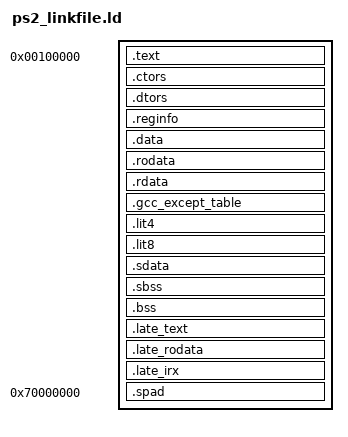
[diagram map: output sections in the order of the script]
/* GENERATED by ps2/tools/gen_arena_glue.py - do not edit.
 *
 * EE link script for the SSB64 port: the ps2sdk default linkfile
 * (Copyright 2001-2004 ps2dev, Academic Free License 2.0) plus one
 * .data and one .bss range per N64 code overlay. On the N64 every
 * syDmaLoadOverlay() re-DMAs an overlay, which resets its initialized data
 * and clears its bss; ps2/src/memory/overlay_state.c reproduces that with
 * these ranges (__ps2_<ovl>_data_start/end, __ps2_<ovl>_bss_start/end).
 */

ENTRY(__start);

PHDRS {
  text PT_LOAD;
}

SECTIONS {
	.text 0x00100000: {
		_ftext = . ;
		*(.text)
		*(.text.*)
		*(.gnu.linkonce.t*)
		KEEP(*(.init))
		KEEP(*(.fini))
		QUAD(0)
	} :text

	PROVIDE(_etext = .);
	PROVIDE(etext = .);

	.ctors ALIGN(16): {
		PROVIDE(__CTOR_LIST__ = .);
		KEEP(*crtbegin*.o(.ctors))
		KEEP(*(EXCLUDE_FILE(*crtend*.o) .ctors))
		KEEP(*(SORT(.ctors.*)))
		KEEP(*(.ctors))
		PROVIDE(__CTOR_END__ = .);
	}
	.dtors ALIGN(16): {
		PROVIDE(__DTOR_LIST__ = .);
		KEEP(*crtbegin*.o(.dtors))
		KEEP(*(EXCLUDE_FILE(*crtend*.o) .dtors))
		KEEP(*(SORT(.dtors.*)))
		KEEP(*(.dtors))
		PROVIDE(__DTOR_END__ = .);
	}

	.reginfo : { *(.reginfo) }

	.data ALIGN(128): {
		_fdata = . ;
		__ps2_ovl_data_start = .;
		. = ALIGN(16); __ps2_ovl0_data_start = .;
		*libssb_game.a:lbcommon.o(.data .data.*)
		*libssb_game.a:lbreloc.o(.data .data.*)
		*libssb_game.a:lbparticle.o(.data .data.*)
		*libssb_game.a:lbfade.o(.data .data.*)
		*libssb_game.a:lbtransition.o(.data .data.*)
		*libssb_game.a:lbbackup.o(.data .data.*)
		__ps2_ovl0_data_end = .;
		. = ALIGN(16); __ps2_ovl1_data_start = .;
		*libssb_game.a:scsubsysunused.o(.data .data.*)
		*libssb_game.a:scsubsysfighter.o(.data .data.*)
		*libssb_game.a:scsubsyscontroller.o(.data .data.*)
		*libssb_game.a:scsubsysdata.o(.data .data.*)
		*libssb_game.a:scsubsysdatamario.o(.data .data.*)
		*libssb_game.a:scsubsysdatammario.o(.data .data.*)
		*libssb_game.a:scsubsysdatanmario.o(.data .data.*)
		*libssb_game.a:scsubsysdatafox.o(.data .data.*)
		*libssb_game.a:scsubsysdatanfox.o(.data .data.*)
		*libssb_game.a:scsubsysdatadonkey.o(.data .data.*)
		*libssb_game.a:scsubsysdatandonkey.o(.data .data.*)
		*libssb_game.a:scsubsysdatagdonkey.o(.data .data.*)
		*libssb_game.a:scsubsysdatasamus.o(.data .data.*)
		*libssb_game.a:scsubsysdatansamus.o(.data .data.*)
		*libssb_game.a:scsubsysdataluigi.o(.data .data.*)
		*libssb_game.a:scsubsysdatanluigi.o(.data .data.*)
		*libssb_game.a:scsubsysdatalink.o(.data .data.*)
		*libssb_game.a:scsubsysdatanlink.o(.data .data.*)
		*libssb_game.a:scsubsysdatayoshi.o(.data .data.*)
		*libssb_game.a:scsubsysdatanyoshi.o(.data .data.*)
		*libssb_game.a:scsubsysdatacaptain.o(.data .data.*)
		*libssb_game.a:scsubsysdatancaptain.o(.data .data.*)
		*libssb_game.a:scsubsysdatakirby.o(.data .data.*)
		*libssb_game.a:scsubsysdatankirby.o(.data .data.*)
		*libssb_game.a:scsubsysdatapikachu.o(.data .data.*)
		*libssb_game.a:scsubsysdatanpikachu.o(.data .data.*)
		*libssb_game.a:scsubsysdatapurin.o(.data .data.*)
		*libssb_game.a:scsubsysdatanpurin.o(.data .data.*)
		*libssb_game.a:scsubsysdataness.o(.data .data.*)
		*libssb_game.a:scsubsysdatanness.o(.data .data.*)
		*libssb_game.a:scsubsysdataboss.o(.data .data.*)
		__ps2_ovl1_data_end = .;
		. = ALIGN(16); __ps2_ovl2_data_start = .;
		*libssb_game.a:sc1pmanager.o(.data .data.*)
		*libssb_game.a:ftmanager.o(.data .data.*)
		*libssb_game.a:ftphysics.o(.data .data.*)
		*libssb_game.a:ftanimend.o(.data .data.*)
		*libssb_game.a:mpprocess.o(.data .data.*)
		*libssb_game.a:mpcommon.o(.data .data.*)
		*libssb_game.a:ftmain.o(.data .data.*)
		*libssb_game.a:ftparam.o(.data .data.*)
		*libssb_game.a:ftanim.o(.data .data.*)
		*libssb_game.a:gmcollision.o(.data .data.*)
		*libssb_game.a:ftdisplaymain.o(.data .data.*)
		*libssb_game.a:fthammer.o(.data .data.*)
		*libssb_game.a:mpcollision.o(.data .data.*)
		*libssb_game.a:ftdisplaylights.o(.data .data.*)
		*libssb_game.a:efdisplay.o(.data .data.*)
		*libssb_game.a:efmanager.o(.data .data.*)
		*libssb_game.a:grwallpaper.o(.data .data.*)
		*libssb_game.a:grdisplay.o(.data .data.*)
		*libssb_game.a:grcommonsetup.o(.data .data.*)
		*libssb_game.a:grmainsetup.o(.data .data.*)
		*libssb_game.a:grmodelsetup.o(.data .data.*)
		*libssb_game.a:grpupupu.o(.data .data.*)
		*libssb_game.a:grsector.o(.data .data.*)
		*libssb_game.a:grzebes.o(.data .data.*)
		*libssb_game.a:gryoster.o(.data .data.*)
		*libssb_game.a:grinishie.o(.data .data.*)
		*libssb_game.a:grjungle.o(.data .data.*)
		*libssb_game.a:grhyrule.o(.data .data.*)
		*libssb_game.a:gryamabuki.o(.data .data.*)
		*libssb_game.a:grcastle.o(.data .data.*)
		*libssb_game.a:grbonus3.o(.data .data.*)
		*libssb_game.a:gmcamera.o(.data .data.*)
		*libssb_game.a:ifcommon.o(.data .data.*)
		*libssb_game.a:gmrumble.o(.data .data.*)
		*libssb_game.a:efparticle.o(.data .data.*)
		*libssb_game.a:ftkey.o(.data .data.*)
		*libssb_game.a:ifscreenflash.o(.data .data.*)
		*libssb_game.a:efground.o(.data .data.*)
		*libssb_game.a:gmcommon.o(.data .data.*)
		*libssb_game.a:ftdata.o(.data .data.*)
		*libssb_game.a:ftcommondata.o(.data .data.*)
		*libssb_game.a:gmcolscripts.o(.data .data.*)
		*libssb_game.a:ftmario.o(.data .data.*)
		*libssb_game.a:ftmmario.o(.data .data.*)
		*libssb_game.a:ftnmario.o(.data .data.*)
		*libssb_game.a:ftfox.o(.data .data.*)
		*libssb_game.a:ftnfox.o(.data .data.*)
		*libssb_game.a:ftdonkey.o(.data .data.*)
		*libssb_game.a:ftndonkey.o(.data .data.*)
		*libssb_game.a:ftgdonkey.o(.data .data.*)
		*libssb_game.a:ftsamus.o(.data .data.*)
		*libssb_game.a:ftnsamus.o(.data .data.*)
		*libssb_game.a:ftluigi.o(.data .data.*)
		*libssb_game.a:ftnluigi.o(.data .data.*)
		*libssb_game.a:ftlink.o(.data .data.*)
		*libssb_game.a:ftnlink.o(.data .data.*)
		*libssb_game.a:ftyoshi.o(.data .data.*)
		*libssb_game.a:ftnyoshi.o(.data .data.*)
		*libssb_game.a:ftcaptain.o(.data .data.*)
		*libssb_game.a:ftncaptain.o(.data .data.*)
		*libssb_game.a:ftkirby.o(.data .data.*)
		*libssb_game.a:ftnkirby.o(.data .data.*)
		*libssb_game.a:ftpikachu.o(.data .data.*)
		*libssb_game.a:ftnpikachu.o(.data .data.*)
		*libssb_game.a:ftpurin.o(.data .data.*)
		*libssb_game.a:ftnpurin.o(.data .data.*)
		*libssb_game.a:ftness.o(.data .data.*)
		*libssb_game.a:ftnness.o(.data .data.*)
		*libssb_game.a:ftboss.o(.data .data.*)
		__ps2_ovl2_data_end = .;
		. = ALIGN(16); __ps2_ovl3_data_start = .;
		*libssb_game.a:ftcomputer.o(.data .data.*)
		*libssb_game.a:ftshadow.o(.data .data.*)
		*libssb_game.a:ftcommondead.o(.data .data.*)
		*libssb_game.a:ftcommonrebirth.o(.data .data.*)
		*libssb_game.a:ftcommonsleep.o(.data .data.*)
		*libssb_game.a:ftcommonentry.o(.data .data.*)
		*libssb_game.a:ftcommonwait.o(.data .data.*)
		*libssb_game.a:ftcommonwalk.o(.data .data.*)
		*libssb_game.a:ftcommonturn.o(.data .data.*)
		*libssb_game.a:ftcommondash.o(.data .data.*)
		*libssb_game.a:ftcommonrun.o(.data .data.*)
		*libssb_game.a:ftcommonrunbrake.o(.data .data.*)
		*libssb_game.a:ftcommonturnrun.o(.data .data.*)
		*libssb_game.a:ftcommonkneebend.o(.data .data.*)
		*libssb_game.a:ftcommonjump.o(.data .data.*)
		*libssb_game.a:ftcommonfall.o(.data .data.*)
		*libssb_game.a:ftcommonjumpaerial.o(.data .data.*)
		*libssb_game.a:ftcommondamage.o(.data .data.*)
		*libssb_game.a:ftcommonwalldamage.o(.data .data.*)
		*libssb_game.a:ftcommonpass.o(.data .data.*)
		*libssb_game.a:ftcommondokan.o(.data .data.*)
		*libssb_game.a:ftcommonottotto.o(.data .data.*)
		*libssb_game.a:ftcommonlanding.o(.data .data.*)
		*libssb_game.a:ftcommonsquat.o(.data .data.*)
		*libssb_game.a:ftcommondamagefall.o(.data .data.*)
		*libssb_game.a:ftcommonfallspecial.o(.data .data.*)
		*libssb_game.a:ftcommontwister.o(.data .data.*)
		*libssb_game.a:ftcommontarucann.o(.data .data.*)
		*libssb_game.a:ftcommonstopceil.o(.data .data.*)
		*libssb_game.a:ftcommondownwaitbounce.o(.data .data.*)
		*libssb_game.a:ftcommondownstand.o(.data .data.*)
		*libssb_game.a:ftcommonpassive.o(.data .data.*)
		*libssb_game.a:ftcommonpassivestand.o(.data .data.*)
		*libssb_game.a:ftcommondownforwardback.o(.data .data.*)
		*libssb_game.a:ftcommondownattack.o(.data .data.*)
		*libssb_game.a:ftcommonrebound.o(.data .data.*)
		*libssb_game.a:ftcommoncliffcatchwait.o(.data .data.*)
		*libssb_game.a:ftcommoncliffclimb.o(.data .data.*)
		*libssb_game.a:ftcommoncliffattack.o(.data .data.*)
		*libssb_game.a:ftcommoncliffescape.o(.data .data.*)
		*libssb_game.a:ftcommonget.o(.data .data.*)
		*libssb_game.a:ftcommonitemthrow.o(.data .data.*)
		*libssb_game.a:ftcommonitemswing.o(.data .data.*)
		*libssb_game.a:ftcommonitemshoot.o(.data .data.*)
		*libssb_game.a:ftcommonhammerwalk.o(.data .data.*)
		*libssb_game.a:ftcommonhammerturn.o(.data .data.*)
		*libssb_game.a:ftcommonhammerfall.o(.data .data.*)
		*libssb_game.a:ftcommonhammerkneebend.o(.data .data.*)
		*libssb_game.a:ftcommonhammerlanding.o(.data .data.*)
		*libssb_game.a:ftcommonguard1.o(.data .data.*)
		*libssb_game.a:ftcommonguard2.o(.data .data.*)
		*libssb_game.a:ftcommonescape.o(.data .data.*)
		*libssb_game.a:ftcommonshieldbreakfly.o(.data .data.*)
		*libssb_game.a:ftcommonshieldbreakdown.o(.data .data.*)
		*libssb_game.a:ftcommonshieldbreakfall.o(.data .data.*)
		*libssb_game.a:ftcommonshieldbreakstand.o(.data .data.*)
		*libssb_game.a:ftcommonfurafura.o(.data .data.*)
		*libssb_game.a:ftcommonfurasleep.o(.data .data.*)
		*libssb_game.a:ftcommoncatch1.o(.data .data.*)
		*libssb_game.a:ftcommoncatch2.o(.data .data.*)
		*libssb_game.a:ftcommonthrow.o(.data .data.*)
		*libssb_game.a:ftkirbythrowf.o(.data .data.*)
		*libssb_game.a:ftcommoncapturepulled.o(.data .data.*)
		*libssb_game.a:ftcommoncapturewait.o(.data .data.*)
		*libssb_game.a:ftcommonthrown1.o(.data .data.*)
		*libssb_game.a:ftcommonthrown2.o(.data .data.*)
		*libssb_game.a:ftcommoncapturekirby.o(.data .data.*)
		*libssb_game.a:ftcommoncaptureyoshi.o(.data .data.*)
		*libssb_game.a:ftcommoncapturecaptain.o(.data .data.*)
		*libssb_game.a:ftdonkeythrowfwait.o(.data .data.*)
		*libssb_game.a:ftdonkeythrowfwalk.o(.data .data.*)
		*libssb_game.a:ftdonkeythrowfturn.o(.data .data.*)
		*libssb_game.a:ftdonkeythrowfkneebend.o(.data .data.*)
		*libssb_game.a:ftdonkeythrowffall.o(.data .data.*)
		*libssb_game.a:ftdonkeythrowflanding.o(.data .data.*)
		*libssb_game.a:ftdonkeythrowff.o(.data .data.*)
		*libssb_game.a:ftdonkeythrowfdamage.o(.data .data.*)
		*libssb_game.a:ftcommoncapture.o(.data .data.*)
		*libssb_game.a:ftcommonappeal.o(.data .data.*)
		*libssb_game.a:ftcommonattack1.o(.data .data.*)
		*libssb_game.a:ftcommonattack100.o(.data .data.*)
		*libssb_game.a:ftcommonattackdash.o(.data .data.*)
		*libssb_game.a:ftcommonattacks3.o(.data .data.*)
		*libssb_game.a:ftcommonattackhi3.o(.data .data.*)
		*libssb_game.a:ftcommonattacklw3.o(.data .data.*)
		*libssb_game.a:ftcommonattacks4.o(.data .data.*)
		*libssb_game.a:ftcommonattackhi4.o(.data .data.*)
		*libssb_game.a:ftcommonattacklw4.o(.data .data.*)
		*libssb_game.a:ftcommonattackair.o(.data .data.*)
		*libssb_game.a:ftcommonlandingair.o(.data .data.*)
		*libssb_game.a:ftcommonspecialair.o(.data .data.*)
		*libssb_game.a:ftcommonspecialn.o(.data .data.*)
		*libssb_game.a:ftcommonspecialhi.o(.data .data.*)
		*libssb_game.a:ftcommonspeciallw.o(.data .data.*)
		*libssb_game.a:ftpurinspecialn.o(.data .data.*)
		*libssb_game.a:ftpurinspecialhi.o(.data .data.*)
		*libssb_game.a:ftpurinspeciallw.o(.data .data.*)
		*libssb_game.a:ftkirbycopypurinspecialn.o(.data .data.*)
		*libssb_game.a:ftpikachuspecialn.o(.data .data.*)
		*libssb_game.a:ftpikachuspeciallw.o(.data .data.*)
		*libssb_game.a:ftpikachuspecialhi.o(.data .data.*)
		*libssb_game.a:ftkirbycopypikachuspecialn.o(.data .data.*)
		*libssb_game.a:ftnessspecialn.o(.data .data.*)
		*libssb_game.a:ftnessspecialhi.o(.data .data.*)
		*libssb_game.a:ftnessspeciallw.o(.data .data.*)
		*libssb_game.a:ftkirbycopynessspecialn.o(.data .data.*)
		*libssb_game.a:ftmariospecialn.o(.data .data.*)
		*libssb_game.a:ftmariospecialhi.o(.data .data.*)
		*libssb_game.a:ftmariospeciallw.o(.data .data.*)
		*libssb_game.a:ftkirbycopymariospecialn.o(.data .data.*)
		*libssb_game.a:ftkirbycopyfoxspecialn.o(.data .data.*)
		*libssb_game.a:ftkirbycopysamusspecialn.o(.data .data.*)
		*libssb_game.a:ftkirbycopydonkeyspecialn.o(.data .data.*)
		*libssb_game.a:ftbosscommon.o(.data .data.*)
		*libssb_game.a:ftbossdefault.o(.data .data.*)
		*libssb_game.a:ftbosswait.o(.data .data.*)
		*libssb_game.a:ftbossmove.o(.data .data.*)
		*libssb_game.a:ftbosshippataku.o(.data .data.*)
		*libssb_game.a:ftbossharau.o(.data .data.*)
		*libssb_game.a:ftbossokuhikouki1.o(.data .data.*)
		*libssb_game.a:ftbossokuhikouki2.o(.data .data.*)
		*libssb_game.a:ftbossokuhikouki3.o(.data .data.*)
		*libssb_game.a:ftbosswalk.o(.data .data.*)
		*libssb_game.a:ftbosswalkloop.o(.data .data.*)
		*libssb_game.a:ftbosswalkwait.o(.data .data.*)
		*libssb_game.a:ftbosswalkshoot.o(.data .data.*)
		*libssb_game.a:ftbossgootsubusuup.o(.data .data.*)
		*libssb_game.a:ftbossgootsubusuwait.o(.data .data.*)
		*libssb_game.a:ftbossgootsubusuend.o(.data .data.*)
		*libssb_game.a:ftbossgootsubusudown.o(.data .data.*)
		*libssb_game.a:ftbosstsutsuku1.o(.data .data.*)
		*libssb_game.a:ftbosstsutsuku3.o(.data .data.*)
		*libssb_game.a:ftbosstsutsuku2.o(.data .data.*)
		*libssb_game.a:ftbossdrill.o(.data .data.*)
		*libssb_game.a:ftbossokukouki.o(.data .data.*)
		*libssb_game.a:ftbossyubideppou1.o(.data .data.*)
		*libssb_game.a:ftbossyubideppou3.o(.data .data.*)
		*libssb_game.a:ftbossyubideppou2.o(.data .data.*)
		*libssb_game.a:ftbossokupunch1.o(.data .data.*)
		*libssb_game.a:ftbossokupunch2.o(.data .data.*)
		*libssb_game.a:ftbossokupunch3.o(.data .data.*)
		*libssb_game.a:ftbossokutsubushi.o(.data .data.*)
		*libssb_game.a:ftbossokutsubushistart.o(.data .data.*)
		*libssb_game.a:ftbossdeadleft.o(.data .data.*)
		*libssb_game.a:ftbossdeadcenter.o(.data .data.*)
		*libssb_game.a:ftbossdeadright.o(.data .data.*)
		*libssb_game.a:ftbossappear.o(.data .data.*)
		*libssb_game.a:ftdonkeyspecialn.o(.data .data.*)
		*libssb_game.a:ftdonkeyspecialhi.o(.data .data.*)
		*libssb_game.a:ftdonkeyspeciallw.o(.data .data.*)
		*libssb_game.a:ftfoxspecialn.o(.data .data.*)
		*libssb_game.a:ftfoxspecialhi.o(.data .data.*)
		*libssb_game.a:ftfoxspeciallw.o(.data .data.*)
		*libssb_game.a:ftsamusspecialn.o(.data .data.*)
		*libssb_game.a:ftsamusspecialhi.o(.data .data.*)
		*libssb_game.a:ftsamusspeciallw.o(.data .data.*)
		*libssb_game.a:ftyoshispecialn.o(.data .data.*)
		*libssb_game.a:ftyoshispecialhi.o(.data .data.*)
		*libssb_game.a:ftyoshispeciallw.o(.data .data.*)
		*libssb_game.a:ftkirbycopyyoshispecialn.o(.data .data.*)
		*libssb_game.a:ftcaptainspecialn.o(.data .data.*)
		*libssb_game.a:ftcaptainspeciallw.o(.data .data.*)
		*libssb_game.a:ftcaptainspecialhi.o(.data .data.*)
		*libssb_game.a:ftkirbycopycaptainspecialn.o(.data .data.*)
		*libssb_game.a:ftkirbyspecialhi.o(.data .data.*)
		*libssb_game.a:ftkirbyspeciallw.o(.data .data.*)
		*libssb_game.a:ftkirbyspecialn.o(.data .data.*)
		*libssb_game.a:ftlinkspecialn.o(.data .data.*)
		*libssb_game.a:ftlinkspecialhi.o(.data .data.*)
		*libssb_game.a:ftlinkspeciallw.o(.data .data.*)
		*libssb_game.a:ftkirbycopylinkspecialn.o(.data .data.*)
		*libssb_game.a:ftpublic.o(.data .data.*)
		*libssb_game.a:wpmanager.o(.data .data.*)
		*libssb_game.a:wpprocess.o(.data .data.*)
		*libssb_game.a:wpdisplay.o(.data .data.*)
		*libssb_game.a:wpmap.o(.data .data.*)
		*libssb_game.a:wpmain.o(.data .data.*)
		*libssb_game.a:wpmariofireball.o(.data .data.*)
		*libssb_game.a:wpfoxblaster.o(.data .data.*)
		*libssb_game.a:wpsamuschargeshot.o(.data .data.*)
		*libssb_game.a:wpsamusbomb.o(.data .data.*)
		*libssb_game.a:wppikachuthunderjolt.o(.data .data.*)
		*libssb_game.a:wppikachuthunder.o(.data .data.*)
		*libssb_game.a:wpnesspkfire.o(.data .data.*)
		*libssb_game.a:wpnesspkthunder.o(.data .data.*)
		*libssb_game.a:wpkirbycutter.o(.data .data.*)
		*libssb_game.a:wpyoshieggthrow.o(.data .data.*)
		*libssb_game.a:wpyoshistar.o(.data .data.*)
		*libssb_game.a:wplinkspinattack.o(.data .data.*)
		*libssb_game.a:wplinkboomerang.o(.data .data.*)
		*libssb_game.a:wpbossbullet.o(.data .data.*)
		*libssb_game.a:itmanager.o(.data .data.*)
		*libssb_game.a:itprocess.o(.data .data.*)
		*libssb_game.a:itvisuals.o(.data .data.*)
		*libssb_game.a:itdisplay.o(.data .data.*)
		*libssb_game.a:itmain.o(.data .data.*)
		*libssb_game.a:itmap.o(.data .data.*)
		*libssb_game.a:itcapsule.o(.data .data.*)
		*libssb_game.a:ittomato.o(.data .data.*)
		*libssb_game.a:itheart.o(.data .data.*)
		*libssb_game.a:itstar.o(.data .data.*)
		*libssb_game.a:itsword.o(.data .data.*)
		*libssb_game.a:itbat.o(.data .data.*)
		*libssb_game.a:itharisen.o(.data .data.*)
		*libssb_game.a:itlgun.o(.data .data.*)
		*libssb_game.a:itfflower.o(.data .data.*)
		*libssb_game.a:ithammer.o(.data .data.*)
		*libssb_game.a:itmsbomb.o(.data .data.*)
		*libssb_game.a:itbombhei.o(.data .data.*)
		*libssb_game.a:itstarrod.o(.data .data.*)
		*libssb_game.a:itgshell.o(.data .data.*)
		*libssb_game.a:itbox.o(.data .data.*)
		*libssb_game.a:ittaru.o(.data .data.*)
		*libssb_game.a:itrshell.o(.data .data.*)
		*libssb_game.a:itnbumper.o(.data .data.*)
		*libssb_game.a:itpowerblock.o(.data .data.*)
		*libssb_game.a:itglucky.o(.data .data.*)
		*libssb_game.a:itmball.o(.data .data.*)
		*libssb_game.a:itpakkun.o(.data .data.*)
		*libssb_game.a:itgbumper.o(.data .data.*)
		*libssb_game.a:itiwark.o(.data .data.*)
		*libssb_game.a:itkabigon.o(.data .data.*)
		*libssb_game.a:ittosakinto.o(.data .data.*)
		*libssb_game.a:itmew.o(.data .data.*)
		*libssb_game.a:itnyars.o(.data .data.*)
		*libssb_game.a:itlizardon.o(.data .data.*)
		*libssb_game.a:itspear.o(.data .data.*)
		*libssb_game.a:itkamex.o(.data .data.*)
		*libssb_game.a:itmlucky.o(.data .data.*)
		*libssb_game.a:itegg.o(.data .data.*)
		*libssb_game.a:itstarmie.o(.data .data.*)
		*libssb_game.a:itsawamura.o(.data .data.*)
		*libssb_game.a:itdogas.o(.data .data.*)
		*libssb_game.a:itpippi.o(.data .data.*)
		*libssb_game.a:itmarumine.o(.data .data.*)
		*libssb_game.a:itporygon.o(.data .data.*)
		*libssb_game.a:ithitokage.o(.data .data.*)
		*libssb_game.a:itfushigibana.o(.data .data.*)
		*libssb_game.a:ittarubomb.o(.data .data.*)
		*libssb_game.a:itnesspkfire.o(.data .data.*)
		*libssb_game.a:itlinkbomb.o(.data .data.*)
		__ps2_ovl3_data_end = .;
		. = ALIGN(16); __ps2_ovl4_data_start = .;
		*libssb_game.a:scvsbattle.o(.data .data.*)
		*libssb_game.a:scvsbattlefiles.o(.data .data.*)
		__ps2_ovl4_data_end = .;
		. = ALIGN(16); __ps2_ovl5_data_start = .;
		*libssb_game.a:mvunknownmario.o(.data .data.*)
		__ps2_ovl5_data_end = .;
		. = ALIGN(16); __ps2_ovl6_data_start = .;
		*libssb_game.a:sc1pbonusstage.o(.data .data.*)
		*libssb_game.a:sc1pbonusstagefiles.o(.data .data.*)
		*libssb_game.a:ittarget.o(.data .data.*)
		__ps2_ovl6_data_end = .;
		. = ALIGN(16); __ps2_ovl7_data_start = .;
		*libssb_game.a:sc1ptrainingmode.o(.data .data.*)
		__ps2_ovl7_data_end = .;
		. = ALIGN(16); __ps2_ovl8_data_start = .;
		*libssb_game.a:ovl8_0.o(.data .data.*)
		*libssb_game.a:ovl8_1.o(.data .data.*)
		*libssb_game.a:ovl8_2.o(.data .data.*)
		*libssb_game.a:ovl8_3.o(.data .data.*)
		*libssb_game.a:ovl8_4.o(.data .data.*)
		*libssb_game.a:ovl8_5.o(.data .data.*)
		*libssb_game.a:ovl8_6.o(.data .data.*)
		*libssb_game.a:ovl8_6_1.o(.data .data.*)
		*libssb_game.a:ovl8_7.o(.data .data.*)
		*libssb_game.a:ovl8_8.o(.data .data.*)
		*libssb_game.a:ovl8_8_2.o(.data .data.*)
		*libssb_game.a:ovl8_9.o(.data .data.*)
		*libssb_game.a:ovl8_10.o(.data .data.*)
		*libssb_game.a:ovl8_11.o(.data .data.*)
		*libssb_game.a:ovl8_11_1.o(.data .data.*)
		*libssb_game.a:ovl8_12.o(.data .data.*)
		*libssb_game.a:ovl8_13.o(.data .data.*)
		*libssb_game.a:ovl8_13_2.o(.data .data.*)
		*libssb_game.a:ovl8_14.o(.data .data.*)
		*libssb_game.a:ovl8_15.o(.data .data.*)
		*libssb_game.a:ovl8_16.o(.data .data.*)
		*libssb_game.a:ovl8_17.o(.data .data.*)
		*libssb_game.a:ovl8_18.o(.data .data.*)
		*libssb_game.a:ovl8_19.o(.data .data.*)
		*libssb_game.a:ovl8_20.o(.data .data.*)
		*libssb_game.a:ovl8_21.o(.data .data.*)
		*libssb_game.a:ovl8_22.o(.data .data.*)
		*libssb_game.a:ovl8_23.o(.data .data.*)
		*libssb_game.a:ovl8_24.o(.data .data.*)
		*libssb_game.a:ovl8_25.o(.data .data.*)
		*libssb_game.a:ovl8_26.o(.data .data.*)
		*libssb_game.a:ovl8_27.o(.data .data.*)
		*libssb_game.a:ovl8_28.o(.data .data.*)
		*libssb_game.a:ovl8_29.o(.data .data.*)
		*libssb_game.a:ovl8_30.o(.data .data.*)
		*libssb_game.a:ovl8_31.o(.data .data.*)
		*libssb_game.a:ovl8_32.o(.data .data.*)
		*libssb_game.a:ovl8_bss.o(.data .data.*)
		__ps2_ovl8_data_end = .;
		. = ALIGN(16); __ps2_ovl9_data_start = .;
		*libssb_game.a:dbmenu.o(.data .data.*)
		__ps2_ovl9_data_end = .;
		. = ALIGN(16); __ps2_ovl10_data_start = .;
		*libssb_game.a:mntitle.o(.data .data.*)
		*libssb_game.a:mntitlefiles.o(.data .data.*)
		__ps2_ovl10_data_end = .;
		. = ALIGN(16); __ps2_ovl11_data_start = .;
		*libssb_game.a:mnnocontroller.o(.data .data.*)
		*libssb_game.a:mnnocontrollerfiles.o(.data .data.*)
		__ps2_ovl11_data_end = .;
		. = ALIGN(16); __ps2_ovl12_data_start = .;
		*libssb_game.a:dbmaps.o(.data .data.*)
		__ps2_ovl12_data_end = .;
		. = ALIGN(16); __ps2_ovl13_data_start = .;
		*libssb_game.a:dbcube.o(.data .data.*)
		__ps2_ovl13_data_end = .;
		. = ALIGN(16); __ps2_ovl14_data_start = .;
		*libssb_game.a:dbbattle.o(.data .data.*)
		__ps2_ovl14_data_end = .;
		. = ALIGN(16); __ps2_ovl15_data_start = .;
		*libssb_game.a:dbfalls.o(.data .data.*)
		__ps2_ovl15_data_end = .;
		. = ALIGN(16); __ps2_ovl16_data_start = .;
		*libssb_game.a:mnunusedfighters.o(.data .data.*)
		__ps2_ovl16_data_end = .;
		. = ALIGN(16); __ps2_ovl17_data_start = .;
		*libssb_game.a:mnmodeselect.o(.data .data.*)
		__ps2_ovl17_data_end = .;
		. = ALIGN(16); __ps2_ovl18_data_start = .;
		*libssb_game.a:mn1pmode.o(.data .data.*)
		__ps2_ovl18_data_end = .;
		. = ALIGN(16); __ps2_ovl19_data_start = .;
		*libssb_game.a:mnvsmode.o(.data .data.*)
		__ps2_ovl19_data_end = .;
		. = ALIGN(16); __ps2_ovl20_data_start = .;
		*libssb_game.a:mnvsoptions.o(.data .data.*)
		__ps2_ovl20_data_end = .;
		. = ALIGN(16); __ps2_ovl21_data_start = .;
		*libssb_game.a:mnvsitemswitch.o(.data .data.*)
		__ps2_ovl21_data_end = .;
		. = ALIGN(16); __ps2_ovl22_data_start = .;
		*libssb_game.a:mnmessage.o(.data .data.*)
		__ps2_ovl22_data_end = .;
		. = ALIGN(16); __ps2_ovl23_data_start = .;
		*libssb_game.a:sc1pchallenger.o(.data .data.*)
		__ps2_ovl23_data_end = .;
		. = ALIGN(16); __ps2_ovl24_data_start = .;
		*libssb_game.a:sc1pintro.o(.data .data.*)
		__ps2_ovl24_data_end = .;
		. = ALIGN(16); __ps2_ovl25_data_start = .;
		*libssb_game.a:mnscreenadjust.o(.data .data.*)
		__ps2_ovl25_data_end = .;
		. = ALIGN(16); __ps2_ovl26_data_start = .;
		*libssb_game.a:mnplayersvs.o(.data .data.*)
		__ps2_ovl26_data_end = .;
		. = ALIGN(16); __ps2_ovl27_data_start = .;
		*libssb_game.a:mnplayers1pgame.o(.data .data.*)
		__ps2_ovl27_data_end = .;
		. = ALIGN(16); __ps2_ovl28_data_start = .;
		*libssb_game.a:mnplayers1ptraining.o(.data .data.*)
		__ps2_ovl28_data_end = .;
		. = ALIGN(16); __ps2_ovl29_data_start = .;
		*libssb_game.a:mnplayers1pbonus.o(.data .data.*)
		__ps2_ovl29_data_end = .;
		. = ALIGN(16); __ps2_ovl30_data_start = .;
		*libssb_game.a:mnmaps.o(.data .data.*)
		__ps2_ovl30_data_end = .;
		. = ALIGN(16); __ps2_ovl31_data_start = .;
		*libssb_game.a:mnvsresults.o(.data .data.*)
		__ps2_ovl31_data_end = .;
		. = ALIGN(16); __ps2_ovl32_data_start = .;
		*libssb_game.a:mnvsrecord.o(.data .data.*)
		__ps2_ovl32_data_end = .;
		. = ALIGN(16); __ps2_ovl33_data_start = .;
		*libssb_game.a:mncharacters.o(.data .data.*)
		__ps2_ovl33_data_end = .;
		. = ALIGN(16); __ps2_ovl34_data_start = .;
		*libssb_game.a:mvopeningroom.o(.data .data.*)
		__ps2_ovl34_data_end = .;
		. = ALIGN(16); __ps2_ovl35_data_start = .;
		*libssb_game.a:mvopeningportraits.o(.data .data.*)
		__ps2_ovl35_data_end = .;
		. = ALIGN(16); __ps2_ovl36_data_start = .;
		*libssb_game.a:mvopeningmario.o(.data .data.*)
		__ps2_ovl36_data_end = .;
		. = ALIGN(16); __ps2_ovl37_data_start = .;
		*libssb_game.a:mvopeningdonkey.o(.data .data.*)
		__ps2_ovl37_data_end = .;
		. = ALIGN(16); __ps2_ovl38_data_start = .;
		*libssb_game.a:mvopeningsamus.o(.data .data.*)
		__ps2_ovl38_data_end = .;
		. = ALIGN(16); __ps2_ovl39_data_start = .;
		*libssb_game.a:mvopeningfox.o(.data .data.*)
		__ps2_ovl39_data_end = .;
		. = ALIGN(16); __ps2_ovl40_data_start = .;
		*libssb_game.a:mvopeninglink.o(.data .data.*)
		__ps2_ovl40_data_end = .;
		. = ALIGN(16); __ps2_ovl41_data_start = .;
		*libssb_game.a:mvopeningyoshi.o(.data .data.*)
		__ps2_ovl41_data_end = .;
		. = ALIGN(16); __ps2_ovl42_data_start = .;
		*libssb_game.a:mvopeningpikachu.o(.data .data.*)
		__ps2_ovl42_data_end = .;
		. = ALIGN(16); __ps2_ovl43_data_start = .;
		*libssb_game.a:mvopeningkirby.o(.data .data.*)
		__ps2_ovl43_data_end = .;
		. = ALIGN(16); __ps2_ovl44_data_start = .;
		*libssb_game.a:mvopeningrun.o(.data .data.*)
		__ps2_ovl44_data_end = .;
		. = ALIGN(16); __ps2_ovl45_data_start = .;
		*libssb_game.a:mvopeningyoster.o(.data .data.*)
		__ps2_ovl45_data_end = .;
		. = ALIGN(16); __ps2_ovl46_data_start = .;
		*libssb_game.a:mvopeningcliff.o(.data .data.*)
		__ps2_ovl46_data_end = .;
		. = ALIGN(16); __ps2_ovl47_data_start = .;
		*libssb_game.a:mvopeningstandoff.o(.data .data.*)
		__ps2_ovl47_data_end = .;
		. = ALIGN(16); __ps2_ovl48_data_start = .;
		*libssb_game.a:mvopeningyamabuki.o(.data .data.*)
		__ps2_ovl48_data_end = .;
		. = ALIGN(16); __ps2_ovl49_data_start = .;
		*libssb_game.a:mvopeningclash.o(.data .data.*)
		__ps2_ovl49_data_end = .;
		. = ALIGN(16); __ps2_ovl50_data_start = .;
		*libssb_game.a:mvopeningsector.o(.data .data.*)
		__ps2_ovl50_data_end = .;
		. = ALIGN(16); __ps2_ovl51_data_start = .;
		*libssb_game.a:mvopeningjungle.o(.data .data.*)
		__ps2_ovl51_data_end = .;
		. = ALIGN(16); __ps2_ovl52_data_start = .;
		*libssb_game.a:mvopeningnewcomers.o(.data .data.*)
		__ps2_ovl52_data_end = .;
		. = ALIGN(16); __ps2_ovl53_data_start = .;
		*libssb_game.a:mnbackupclear.o(.data .data.*)
		__ps2_ovl53_data_end = .;
		. = ALIGN(16); __ps2_ovl54_data_start = .;
		*libssb_game.a:mvending.o(.data .data.*)
		__ps2_ovl54_data_end = .;
		. = ALIGN(16); __ps2_ovl55_data_start = .;
		*libssb_game.a:mn1pcontinue.o(.data .data.*)
		__ps2_ovl55_data_end = .;
		. = ALIGN(16); __ps2_ovl56_data_start = .;
		*libssb_game.a:sc1pstageclear.o(.data .data.*)
		__ps2_ovl56_data_end = .;
		. = ALIGN(16); __ps2_ovl57_data_start = .;
		*libssb_game.a:mncongra.o(.data .data.*)
		__ps2_ovl57_data_end = .;
		. = ALIGN(16); __ps2_ovl58_data_start = .;
		*libssb_game.a:mnstartup.o(.data .data.*)
		__ps2_ovl58_data_end = .;
		. = ALIGN(16); __ps2_ovl59_data_start = .;
		*libssb_game.a:scstaffroll.o(.data .data.*)
		__ps2_ovl59_data_end = .;
		. = ALIGN(16); __ps2_ovl60_data_start = .;
		*libssb_game.a:mnoption.o(.data .data.*)
		__ps2_ovl60_data_end = .;
		. = ALIGN(16); __ps2_ovl61_data_start = .;
		*libssb_game.a:mndata.o(.data .data.*)
		__ps2_ovl61_data_end = .;
		. = ALIGN(16); __ps2_ovl62_data_start = .;
		*libssb_game.a:mnsoundtest.o(.data .data.*)
		__ps2_ovl62_data_end = .;
		. = ALIGN(16); __ps2_ovl63_data_start = .;
		*libssb_game.a:scexplain.o(.data .data.*)
		*libssb_game.a:scexplainfiles.o(.data .data.*)
		__ps2_ovl63_data_end = .;
		. = ALIGN(16); __ps2_ovl64_data_start = .;
		*libssb_game.a:scautodemo.o(.data .data.*)
		*libssb_game.a:scautodemofiles.o(.data .data.*)
		__ps2_ovl64_data_end = .;
		. = ALIGN(16); __ps2_ovl65_data_start = .;
		*libssb_game.a:sc1pgame.o(.data .data.*)
		*libssb_game.a:sc1pgameboss.o(.data .data.*)
		__ps2_ovl65_data_end = .;
		. = ALIGN(16); __ps2_scmanager_data_start = .;
		*libssb_game.a:scmanager.o(.data .data.*)
		__ps2_scmanager_data_end = .;
		__ps2_ovl_data_end = .;
		*(EXCLUDE_FILE(*sdr_irx.o) .data)
		*(EXCLUDE_FILE(*sdr_irx.o) .data.*)
		*(.gnu.linkonce.d*)
		SORT(CONSTRUCTORS)
	}

	.rodata ALIGN(128): {
		*(.rodata)
		*(.rodata.*)
		*(.gnu.linkonce.r*)
	}

	.rdata ALIGN(128): { *(.rdata) }
	.gcc_except_table ALIGN(128): { *(.gcc_except_table) }

	_gp = ALIGN(128) + 0x7ff0;
	.lit4 ALIGN(128): { *(.lit4) }
	.lit8 ALIGN(128): { *(.lit8) }

	.sdata ALIGN(128): {
		*(.sdata)
		*(.sdata.*)
		*(.gnu.linkonce.s*)
	}

	_edata = .;
	PROVIDE(edata = .);

	.sbss ALIGN(128) : {
		_fbss = . ;
		*(.sbss)
		*(.sbss.*)
		*(.gnu.linkonce.sb*)
		*(.scommon)
	}

	.bss ALIGN(128) : {
		. = ALIGN(16); __ps2_ovl0_bss_start = .;
		*libssb_game.a:lbcommon.o(.bss .bss.* COMMON)
		*libssb_game.a:lbreloc.o(.bss .bss.* COMMON)
		*libssb_game.a:lbparticle.o(.bss .bss.* COMMON)
		*libssb_game.a:lbfade.o(.bss .bss.* COMMON)
		*libssb_game.a:lbtransition.o(.bss .bss.* COMMON)
		*libssb_game.a:lbbackup.o(.bss .bss.* COMMON)
		__ps2_ovl0_bss_end = .;
		. = ALIGN(16); __ps2_ovl1_bss_start = .;
		*libssb_game.a:scsubsysunused.o(.bss .bss.* COMMON)
		*libssb_game.a:scsubsysfighter.o(.bss .bss.* COMMON)
		*libssb_game.a:scsubsyscontroller.o(.bss .bss.* COMMON)
		*libssb_game.a:scsubsysdata.o(.bss .bss.* COMMON)
		*libssb_game.a:scsubsysdatamario.o(.bss .bss.* COMMON)
		*libssb_game.a:scsubsysdatammario.o(.bss .bss.* COMMON)
		*libssb_game.a:scsubsysdatanmario.o(.bss .bss.* COMMON)
		*libssb_game.a:scsubsysdatafox.o(.bss .bss.* COMMON)
		*libssb_game.a:scsubsysdatanfox.o(.bss .bss.* COMMON)
		*libssb_game.a:scsubsysdatadonkey.o(.bss .bss.* COMMON)
		*libssb_game.a:scsubsysdatandonkey.o(.bss .bss.* COMMON)
		*libssb_game.a:scsubsysdatagdonkey.o(.bss .bss.* COMMON)
		*libssb_game.a:scsubsysdatasamus.o(.bss .bss.* COMMON)
		*libssb_game.a:scsubsysdatansamus.o(.bss .bss.* COMMON)
		*libssb_game.a:scsubsysdataluigi.o(.bss .bss.* COMMON)
		*libssb_game.a:scsubsysdatanluigi.o(.bss .bss.* COMMON)
		*libssb_game.a:scsubsysdatalink.o(.bss .bss.* COMMON)
		*libssb_game.a:scsubsysdatanlink.o(.bss .bss.* COMMON)
		*libssb_game.a:scsubsysdatayoshi.o(.bss .bss.* COMMON)
		*libssb_game.a:scsubsysdatanyoshi.o(.bss .bss.* COMMON)
		*libssb_game.a:scsubsysdatacaptain.o(.bss .bss.* COMMON)
		*libssb_game.a:scsubsysdatancaptain.o(.bss .bss.* COMMON)
		*libssb_game.a:scsubsysdatakirby.o(.bss .bss.* COMMON)
		*libssb_game.a:scsubsysdatankirby.o(.bss .bss.* COMMON)
		*libssb_game.a:scsubsysdatapikachu.o(.bss .bss.* COMMON)
		*libssb_game.a:scsubsysdatanpikachu.o(.bss .bss.* COMMON)
		*libssb_game.a:scsubsysdatapurin.o(.bss .bss.* COMMON)
		*libssb_game.a:scsubsysdatanpurin.o(.bss .bss.* COMMON)
		*libssb_game.a:scsubsysdataness.o(.bss .bss.* COMMON)
		*libssb_game.a:scsubsysdatanness.o(.bss .bss.* COMMON)
		*libssb_game.a:scsubsysdataboss.o(.bss .bss.* COMMON)
		__ps2_ovl1_bss_end = .;
		. = ALIGN(16); __ps2_ovl2_bss_start = .;
		*libssb_game.a:sc1pmanager.o(.bss .bss.* COMMON)
		*libssb_game.a:ftmanager.o(.bss .bss.* COMMON)
		*libssb_game.a:ftphysics.o(.bss .bss.* COMMON)
		*libssb_game.a:ftanimend.o(.bss .bss.* COMMON)
		*libssb_game.a:mpprocess.o(.bss .bss.* COMMON)
		*libssb_game.a:mpcommon.o(.bss .bss.* COMMON)
		*libssb_game.a:ftmain.o(.bss .bss.* COMMON)
		*libssb_game.a:ftparam.o(.bss .bss.* COMMON)
		*libssb_game.a:ftanim.o(.bss .bss.* COMMON)
		*libssb_game.a:gmcollision.o(.bss .bss.* COMMON)
		*libssb_game.a:ftdisplaymain.o(.bss .bss.* COMMON)
		*libssb_game.a:fthammer.o(.bss .bss.* COMMON)
		*libssb_game.a:mpcollision.o(.bss .bss.* COMMON)
		*libssb_game.a:ftdisplaylights.o(.bss .bss.* COMMON)
		*libssb_game.a:efdisplay.o(.bss .bss.* COMMON)
		*libssb_game.a:efmanager.o(.bss .bss.* COMMON)
		*libssb_game.a:grwallpaper.o(.bss .bss.* COMMON)
		*libssb_game.a:grdisplay.o(.bss .bss.* COMMON)
		*libssb_game.a:grcommonsetup.o(.bss .bss.* COMMON)
		*libssb_game.a:grmainsetup.o(.bss .bss.* COMMON)
		*libssb_game.a:grmodelsetup.o(.bss .bss.* COMMON)
		*libssb_game.a:grpupupu.o(.bss .bss.* COMMON)
		*libssb_game.a:grsector.o(.bss .bss.* COMMON)
		*libssb_game.a:grzebes.o(.bss .bss.* COMMON)
		*libssb_game.a:gryoster.o(.bss .bss.* COMMON)
		*libssb_game.a:grinishie.o(.bss .bss.* COMMON)
		*libssb_game.a:grjungle.o(.bss .bss.* COMMON)
		*libssb_game.a:grhyrule.o(.bss .bss.* COMMON)
		*libssb_game.a:gryamabuki.o(.bss .bss.* COMMON)
		*libssb_game.a:grcastle.o(.bss .bss.* COMMON)
		*libssb_game.a:grbonus3.o(.bss .bss.* COMMON)
		*libssb_game.a:gmcamera.o(.bss .bss.* COMMON)
		*libssb_game.a:ifcommon.o(.bss .bss.* COMMON)
		*libssb_game.a:gmrumble.o(.bss .bss.* COMMON)
		*libssb_game.a:efparticle.o(.bss .bss.* COMMON)
		*libssb_game.a:ftkey.o(.bss .bss.* COMMON)
		*libssb_game.a:ifscreenflash.o(.bss .bss.* COMMON)
		*libssb_game.a:efground.o(.bss .bss.* COMMON)
		*libssb_game.a:gmcommon.o(.bss .bss.* COMMON)
		*libssb_game.a:ftdata.o(.bss .bss.* COMMON)
		*libssb_game.a:ftcommondata.o(.bss .bss.* COMMON)
		*libssb_game.a:gmcolscripts.o(.bss .bss.* COMMON)
		*libssb_game.a:ftmario.o(.bss .bss.* COMMON)
		*libssb_game.a:ftmmario.o(.bss .bss.* COMMON)
		*libssb_game.a:ftnmario.o(.bss .bss.* COMMON)
		*libssb_game.a:ftfox.o(.bss .bss.* COMMON)
		*libssb_game.a:ftnfox.o(.bss .bss.* COMMON)
		*libssb_game.a:ftdonkey.o(.bss .bss.* COMMON)
		*libssb_game.a:ftndonkey.o(.bss .bss.* COMMON)
		*libssb_game.a:ftgdonkey.o(.bss .bss.* COMMON)
		*libssb_game.a:ftsamus.o(.bss .bss.* COMMON)
		*libssb_game.a:ftnsamus.o(.bss .bss.* COMMON)
		*libssb_game.a:ftluigi.o(.bss .bss.* COMMON)
		*libssb_game.a:ftnluigi.o(.bss .bss.* COMMON)
		*libssb_game.a:ftlink.o(.bss .bss.* COMMON)
		*libssb_game.a:ftnlink.o(.bss .bss.* COMMON)
		*libssb_game.a:ftyoshi.o(.bss .bss.* COMMON)
		*libssb_game.a:ftnyoshi.o(.bss .bss.* COMMON)
		*libssb_game.a:ftcaptain.o(.bss .bss.* COMMON)
		*libssb_game.a:ftncaptain.o(.bss .bss.* COMMON)
		*libssb_game.a:ftkirby.o(.bss .bss.* COMMON)
		*libssb_game.a:ftnkirby.o(.bss .bss.* COMMON)
		*libssb_game.a:ftpikachu.o(.bss .bss.* COMMON)
		*libssb_game.a:ftnpikachu.o(.bss .bss.* COMMON)
		*libssb_game.a:ftpurin.o(.bss .bss.* COMMON)
		*libssb_game.a:ftnpurin.o(.bss .bss.* COMMON)
		*libssb_game.a:ftness.o(.bss .bss.* COMMON)
		*libssb_game.a:ftnness.o(.bss .bss.* COMMON)
		*libssb_game.a:ftboss.o(.bss .bss.* COMMON)
		__ps2_ovl2_bss_end = .;
		. = ALIGN(16); __ps2_ovl3_bss_start = .;
		*libssb_game.a:ftcomputer.o(.bss .bss.* COMMON)
		*libssb_game.a:ftshadow.o(.bss .bss.* COMMON)
		*libssb_game.a:ftcommondead.o(.bss .bss.* COMMON)
		*libssb_game.a:ftcommonrebirth.o(.bss .bss.* COMMON)
		*libssb_game.a:ftcommonsleep.o(.bss .bss.* COMMON)
		*libssb_game.a:ftcommonentry.o(.bss .bss.* COMMON)
		*libssb_game.a:ftcommonwait.o(.bss .bss.* COMMON)
		*libssb_game.a:ftcommonwalk.o(.bss .bss.* COMMON)
		*libssb_game.a:ftcommonturn.o(.bss .bss.* COMMON)
		*libssb_game.a:ftcommondash.o(.bss .bss.* COMMON)
		*libssb_game.a:ftcommonrun.o(.bss .bss.* COMMON)
		*libssb_game.a:ftcommonrunbrake.o(.bss .bss.* COMMON)
		*libssb_game.a:ftcommonturnrun.o(.bss .bss.* COMMON)
		*libssb_game.a:ftcommonkneebend.o(.bss .bss.* COMMON)
		*libssb_game.a:ftcommonjump.o(.bss .bss.* COMMON)
		*libssb_game.a:ftcommonfall.o(.bss .bss.* COMMON)
		*libssb_game.a:ftcommonjumpaerial.o(.bss .bss.* COMMON)
		*libssb_game.a:ftcommondamage.o(.bss .bss.* COMMON)
		*libssb_game.a:ftcommonwalldamage.o(.bss .bss.* COMMON)
		*libssb_game.a:ftcommonpass.o(.bss .bss.* COMMON)
		*libssb_game.a:ftcommondokan.o(.bss .bss.* COMMON)
		*libssb_game.a:ftcommonottotto.o(.bss .bss.* COMMON)
		*libssb_game.a:ftcommonlanding.o(.bss .bss.* COMMON)
		*libssb_game.a:ftcommonsquat.o(.bss .bss.* COMMON)
		*libssb_game.a:ftcommondamagefall.o(.bss .bss.* COMMON)
		*libssb_game.a:ftcommonfallspecial.o(.bss .bss.* COMMON)
		*libssb_game.a:ftcommontwister.o(.bss .bss.* COMMON)
		*libssb_game.a:ftcommontarucann.o(.bss .bss.* COMMON)
		*libssb_game.a:ftcommonstopceil.o(.bss .bss.* COMMON)
		*libssb_game.a:ftcommondownwaitbounce.o(.bss .bss.* COMMON)
		*libssb_game.a:ftcommondownstand.o(.bss .bss.* COMMON)
		*libssb_game.a:ftcommonpassive.o(.bss .bss.* COMMON)
		*libssb_game.a:ftcommonpassivestand.o(.bss .bss.* COMMON)
		*libssb_game.a:ftcommondownforwardback.o(.bss .bss.* COMMON)
		*libssb_game.a:ftcommondownattack.o(.bss .bss.* COMMON)
		*libssb_game.a:ftcommonrebound.o(.bss .bss.* COMMON)
		*libssb_game.a:ftcommoncliffcatchwait.o(.bss .bss.* COMMON)
		*libssb_game.a:ftcommoncliffclimb.o(.bss .bss.* COMMON)
		*libssb_game.a:ftcommoncliffattack.o(.bss .bss.* COMMON)
		*libssb_game.a:ftcommoncliffescape.o(.bss .bss.* COMMON)
		*libssb_game.a:ftcommonget.o(.bss .bss.* COMMON)
		*libssb_game.a:ftcommonitemthrow.o(.bss .bss.* COMMON)
		*libssb_game.a:ftcommonitemswing.o(.bss .bss.* COMMON)
		*libssb_game.a:ftcommonitemshoot.o(.bss .bss.* COMMON)
		*libssb_game.a:ftcommonhammerwalk.o(.bss .bss.* COMMON)
		*libssb_game.a:ftcommonhammerturn.o(.bss .bss.* COMMON)
		*libssb_game.a:ftcommonhammerfall.o(.bss .bss.* COMMON)
		*libssb_game.a:ftcommonhammerkneebend.o(.bss .bss.* COMMON)
		*libssb_game.a:ftcommonhammerlanding.o(.bss .bss.* COMMON)
		*libssb_game.a:ftcommonguard1.o(.bss .bss.* COMMON)
		*libssb_game.a:ftcommonguard2.o(.bss .bss.* COMMON)
		*libssb_game.a:ftcommonescape.o(.bss .bss.* COMMON)
		*libssb_game.a:ftcommonshieldbreakfly.o(.bss .bss.* COMMON)
		*libssb_game.a:ftcommonshieldbreakdown.o(.bss .bss.* COMMON)
		*libssb_game.a:ftcommonshieldbreakfall.o(.bss .bss.* COMMON)
		*libssb_game.a:ftcommonshieldbreakstand.o(.bss .bss.* COMMON)
		*libssb_game.a:ftcommonfurafura.o(.bss .bss.* COMMON)
		*libssb_game.a:ftcommonfurasleep.o(.bss .bss.* COMMON)
		*libssb_game.a:ftcommoncatch1.o(.bss .bss.* COMMON)
		*libssb_game.a:ftcommoncatch2.o(.bss .bss.* COMMON)
		*libssb_game.a:ftcommonthrow.o(.bss .bss.* COMMON)
		*libssb_game.a:ftkirbythrowf.o(.bss .bss.* COMMON)
		*libssb_game.a:ftcommoncapturepulled.o(.bss .bss.* COMMON)
		*libssb_game.a:ftcommoncapturewait.o(.bss .bss.* COMMON)
		*libssb_game.a:ftcommonthrown1.o(.bss .bss.* COMMON)
		*libssb_game.a:ftcommonthrown2.o(.bss .bss.* COMMON)
		*libssb_game.a:ftcommoncapturekirby.o(.bss .bss.* COMMON)
		*libssb_game.a:ftcommoncaptureyoshi.o(.bss .bss.* COMMON)
		*libssb_game.a:ftcommoncapturecaptain.o(.bss .bss.* COMMON)
		*libssb_game.a:ftdonkeythrowfwait.o(.bss .bss.* COMMON)
		*libssb_game.a:ftdonkeythrowfwalk.o(.bss .bss.* COMMON)
		*libssb_game.a:ftdonkeythrowfturn.o(.bss .bss.* COMMON)
		*libssb_game.a:ftdonkeythrowfkneebend.o(.bss .bss.* COMMON)
		*libssb_game.a:ftdonkeythrowffall.o(.bss .bss.* COMMON)
		*libssb_game.a:ftdonkeythrowflanding.o(.bss .bss.* COMMON)
		*libssb_game.a:ftdonkeythrowff.o(.bss .bss.* COMMON)
		*libssb_game.a:ftdonkeythrowfdamage.o(.bss .bss.* COMMON)
		*libssb_game.a:ftcommoncapture.o(.bss .bss.* COMMON)
		*libssb_game.a:ftcommonappeal.o(.bss .bss.* COMMON)
		*libssb_game.a:ftcommonattack1.o(.bss .bss.* COMMON)
		*libssb_game.a:ftcommonattack100.o(.bss .bss.* COMMON)
		*libssb_game.a:ftcommonattackdash.o(.bss .bss.* COMMON)
		*libssb_game.a:ftcommonattacks3.o(.bss .bss.* COMMON)
		*libssb_game.a:ftcommonattackhi3.o(.bss .bss.* COMMON)
		*libssb_game.a:ftcommonattacklw3.o(.bss .bss.* COMMON)
		*libssb_game.a:ftcommonattacks4.o(.bss .bss.* COMMON)
		*libssb_game.a:ftcommonattackhi4.o(.bss .bss.* COMMON)
		*libssb_game.a:ftcommonattacklw4.o(.bss .bss.* COMMON)
		*libssb_game.a:ftcommonattackair.o(.bss .bss.* COMMON)
		*libssb_game.a:ftcommonlandingair.o(.bss .bss.* COMMON)
		*libssb_game.a:ftcommonspecialair.o(.bss .bss.* COMMON)
		*libssb_game.a:ftcommonspecialn.o(.bss .bss.* COMMON)
		*libssb_game.a:ftcommonspecialhi.o(.bss .bss.* COMMON)
		*libssb_game.a:ftcommonspeciallw.o(.bss .bss.* COMMON)
		*libssb_game.a:ftpurinspecialn.o(.bss .bss.* COMMON)
		*libssb_game.a:ftpurinspecialhi.o(.bss .bss.* COMMON)
		*libssb_game.a:ftpurinspeciallw.o(.bss .bss.* COMMON)
		*libssb_game.a:ftkirbycopypurinspecialn.o(.bss .bss.* COMMON)
		*libssb_game.a:ftpikachuspecialn.o(.bss .bss.* COMMON)
		*libssb_game.a:ftpikachuspeciallw.o(.bss .bss.* COMMON)
		*libssb_game.a:ftpikachuspecialhi.o(.bss .bss.* COMMON)
		*libssb_game.a:ftkirbycopypikachuspecialn.o(.bss .bss.* COMMON)
		*libssb_game.a:ftnessspecialn.o(.bss .bss.* COMMON)
		*libssb_game.a:ftnessspecialhi.o(.bss .bss.* COMMON)
		*libssb_game.a:ftnessspeciallw.o(.bss .bss.* COMMON)
		*libssb_game.a:ftkirbycopynessspecialn.o(.bss .bss.* COMMON)
		*libssb_game.a:ftmariospecialn.o(.bss .bss.* COMMON)
		*libssb_game.a:ftmariospecialhi.o(.bss .bss.* COMMON)
		*libssb_game.a:ftmariospeciallw.o(.bss .bss.* COMMON)
		*libssb_game.a:ftkirbycopymariospecialn.o(.bss .bss.* COMMON)
		*libssb_game.a:ftkirbycopyfoxspecialn.o(.bss .bss.* COMMON)
		*libssb_game.a:ftkirbycopysamusspecialn.o(.bss .bss.* COMMON)
		*libssb_game.a:ftkirbycopydonkeyspecialn.o(.bss .bss.* COMMON)
		*libssb_game.a:ftbosscommon.o(.bss .bss.* COMMON)
		*libssb_game.a:ftbossdefault.o(.bss .bss.* COMMON)
		*libssb_game.a:ftbosswait.o(.bss .bss.* COMMON)
		*libssb_game.a:ftbossmove.o(.bss .bss.* COMMON)
		*libssb_game.a:ftbosshippataku.o(.bss .bss.* COMMON)
		*libssb_game.a:ftbossharau.o(.bss .bss.* COMMON)
		*libssb_game.a:ftbossokuhikouki1.o(.bss .bss.* COMMON)
		*libssb_game.a:ftbossokuhikouki2.o(.bss .bss.* COMMON)
		*libssb_game.a:ftbossokuhikouki3.o(.bss .bss.* COMMON)
		*libssb_game.a:ftbosswalk.o(.bss .bss.* COMMON)
		*libssb_game.a:ftbosswalkloop.o(.bss .bss.* COMMON)
		*libssb_game.a:ftbosswalkwait.o(.bss .bss.* COMMON)
		*libssb_game.a:ftbosswalkshoot.o(.bss .bss.* COMMON)
		*libssb_game.a:ftbossgootsubusuup.o(.bss .bss.* COMMON)
		*libssb_game.a:ftbossgootsubusuwait.o(.bss .bss.* COMMON)
		*libssb_game.a:ftbossgootsubusuend.o(.bss .bss.* COMMON)
		*libssb_game.a:ftbossgootsubusudown.o(.bss .bss.* COMMON)
		*libssb_game.a:ftbosstsutsuku1.o(.bss .bss.* COMMON)
		*libssb_game.a:ftbosstsutsuku3.o(.bss .bss.* COMMON)
		*libssb_game.a:ftbosstsutsuku2.o(.bss .bss.* COMMON)
		*libssb_game.a:ftbossdrill.o(.bss .bss.* COMMON)
		*libssb_game.a:ftbossokukouki.o(.bss .bss.* COMMON)
		*libssb_game.a:ftbossyubideppou1.o(.bss .bss.* COMMON)
		*libssb_game.a:ftbossyubideppou3.o(.bss .bss.* COMMON)
		*libssb_game.a:ftbossyubideppou2.o(.bss .bss.* COMMON)
		*libssb_game.a:ftbossokupunch1.o(.bss .bss.* COMMON)
		*libssb_game.a:ftbossokupunch2.o(.bss .bss.* COMMON)
		*libssb_game.a:ftbossokupunch3.o(.bss .bss.* COMMON)
		*libssb_game.a:ftbossokutsubushi.o(.bss .bss.* COMMON)
		*libssb_game.a:ftbossokutsubushistart.o(.bss .bss.* COMMON)
		*libssb_game.a:ftbossdeadleft.o(.bss .bss.* COMMON)
		*libssb_game.a:ftbossdeadcenter.o(.bss .bss.* COMMON)
		*libssb_game.a:ftbossdeadright.o(.bss .bss.* COMMON)
		*libssb_game.a:ftbossappear.o(.bss .bss.* COMMON)
		*libssb_game.a:ftdonkeyspecialn.o(.bss .bss.* COMMON)
		*libssb_game.a:ftdonkeyspecialhi.o(.bss .bss.* COMMON)
		*libssb_game.a:ftdonkeyspeciallw.o(.bss .bss.* COMMON)
		*libssb_game.a:ftfoxspecialn.o(.bss .bss.* COMMON)
		*libssb_game.a:ftfoxspecialhi.o(.bss .bss.* COMMON)
		*libssb_game.a:ftfoxspeciallw.o(.bss .bss.* COMMON)
		*libssb_game.a:ftsamusspecialn.o(.bss .bss.* COMMON)
		*libssb_game.a:ftsamusspecialhi.o(.bss .bss.* COMMON)
		*libssb_game.a:ftsamusspeciallw.o(.bss .bss.* COMMON)
		*libssb_game.a:ftyoshispecialn.o(.bss .bss.* COMMON)
		*libssb_game.a:ftyoshispecialhi.o(.bss .bss.* COMMON)
		*libssb_game.a:ftyoshispeciallw.o(.bss .bss.* COMMON)
		*libssb_game.a:ftkirbycopyyoshispecialn.o(.bss .bss.* COMMON)
		*libssb_game.a:ftcaptainspecialn.o(.bss .bss.* COMMON)
		*libssb_game.a:ftcaptainspeciallw.o(.bss .bss.* COMMON)
		*libssb_game.a:ftcaptainspecialhi.o(.bss .bss.* COMMON)
		*libssb_game.a:ftkirbycopycaptainspecialn.o(.bss .bss.* COMMON)
		*libssb_game.a:ftkirbyspecialhi.o(.bss .bss.* COMMON)
		*libssb_game.a:ftkirbyspeciallw.o(.bss .bss.* COMMON)
		*libssb_game.a:ftkirbyspecialn.o(.bss .bss.* COMMON)
		*libssb_game.a:ftlinkspecialn.o(.bss .bss.* COMMON)
		*libssb_game.a:ftlinkspecialhi.o(.bss .bss.* COMMON)
		*libssb_game.a:ftlinkspeciallw.o(.bss .bss.* COMMON)
		*libssb_game.a:ftkirbycopylinkspecialn.o(.bss .bss.* COMMON)
		*libssb_game.a:ftpublic.o(.bss .bss.* COMMON)
		*libssb_game.a:wpmanager.o(.bss .bss.* COMMON)
		*libssb_game.a:wpprocess.o(.bss .bss.* COMMON)
		*libssb_game.a:wpdisplay.o(.bss .bss.* COMMON)
		*libssb_game.a:wpmap.o(.bss .bss.* COMMON)
		*libssb_game.a:wpmain.o(.bss .bss.* COMMON)
		*libssb_game.a:wpmariofireball.o(.bss .bss.* COMMON)
		*libssb_game.a:wpfoxblaster.o(.bss .bss.* COMMON)
		*libssb_game.a:wpsamuschargeshot.o(.bss .bss.* COMMON)
		*libssb_game.a:wpsamusbomb.o(.bss .bss.* COMMON)
		*libssb_game.a:wppikachuthunderjolt.o(.bss .bss.* COMMON)
		*libssb_game.a:wppikachuthunder.o(.bss .bss.* COMMON)
		*libssb_game.a:wpnesspkfire.o(.bss .bss.* COMMON)
		*libssb_game.a:wpnesspkthunder.o(.bss .bss.* COMMON)
		*libssb_game.a:wpkirbycutter.o(.bss .bss.* COMMON)
		*libssb_game.a:wpyoshieggthrow.o(.bss .bss.* COMMON)
		*libssb_game.a:wpyoshistar.o(.bss .bss.* COMMON)
		*libssb_game.a:wplinkspinattack.o(.bss .bss.* COMMON)
		*libssb_game.a:wplinkboomerang.o(.bss .bss.* COMMON)
		*libssb_game.a:wpbossbullet.o(.bss .bss.* COMMON)
		*libssb_game.a:itmanager.o(.bss .bss.* COMMON)
		*libssb_game.a:itprocess.o(.bss .bss.* COMMON)
		*libssb_game.a:itvisuals.o(.bss .bss.* COMMON)
		*libssb_game.a:itdisplay.o(.bss .bss.* COMMON)
		*libssb_game.a:itmain.o(.bss .bss.* COMMON)
		*libssb_game.a:itmap.o(.bss .bss.* COMMON)
		*libssb_game.a:itcapsule.o(.bss .bss.* COMMON)
		*libssb_game.a:ittomato.o(.bss .bss.* COMMON)
		*libssb_game.a:itheart.o(.bss .bss.* COMMON)
		*libssb_game.a:itstar.o(.bss .bss.* COMMON)
		*libssb_game.a:itsword.o(.bss .bss.* COMMON)
		*libssb_game.a:itbat.o(.bss .bss.* COMMON)
		*libssb_game.a:itharisen.o(.bss .bss.* COMMON)
		*libssb_game.a:itlgun.o(.bss .bss.* COMMON)
		*libssb_game.a:itfflower.o(.bss .bss.* COMMON)
		*libssb_game.a:ithammer.o(.bss .bss.* COMMON)
		*libssb_game.a:itmsbomb.o(.bss .bss.* COMMON)
		*libssb_game.a:itbombhei.o(.bss .bss.* COMMON)
		*libssb_game.a:itstarrod.o(.bss .bss.* COMMON)
		*libssb_game.a:itgshell.o(.bss .bss.* COMMON)
		*libssb_game.a:itbox.o(.bss .bss.* COMMON)
		*libssb_game.a:ittaru.o(.bss .bss.* COMMON)
		*libssb_game.a:itrshell.o(.bss .bss.* COMMON)
		*libssb_game.a:itnbumper.o(.bss .bss.* COMMON)
		*libssb_game.a:itpowerblock.o(.bss .bss.* COMMON)
		*libssb_game.a:itglucky.o(.bss .bss.* COMMON)
		*libssb_game.a:itmball.o(.bss .bss.* COMMON)
		*libssb_game.a:itpakkun.o(.bss .bss.* COMMON)
		*libssb_game.a:itgbumper.o(.bss .bss.* COMMON)
		*libssb_game.a:itiwark.o(.bss .bss.* COMMON)
		*libssb_game.a:itkabigon.o(.bss .bss.* COMMON)
		*libssb_game.a:ittosakinto.o(.bss .bss.* COMMON)
		*libssb_game.a:itmew.o(.bss .bss.* COMMON)
		*libssb_game.a:itnyars.o(.bss .bss.* COMMON)
		*libssb_game.a:itlizardon.o(.bss .bss.* COMMON)
		*libssb_game.a:itspear.o(.bss .bss.* COMMON)
		*libssb_game.a:itkamex.o(.bss .bss.* COMMON)
		*libssb_game.a:itmlucky.o(.bss .bss.* COMMON)
		*libssb_game.a:itegg.o(.bss .bss.* COMMON)
		*libssb_game.a:itstarmie.o(.bss .bss.* COMMON)
		*libssb_game.a:itsawamura.o(.bss .bss.* COMMON)
		*libssb_game.a:itdogas.o(.bss .bss.* COMMON)
		*libssb_game.a:itpippi.o(.bss .bss.* COMMON)
		*libssb_game.a:itmarumine.o(.bss .bss.* COMMON)
		*libssb_game.a:itporygon.o(.bss .bss.* COMMON)
		*libssb_game.a:ithitokage.o(.bss .bss.* COMMON)
		*libssb_game.a:itfushigibana.o(.bss .bss.* COMMON)
		*libssb_game.a:ittarubomb.o(.bss .bss.* COMMON)
		*libssb_game.a:itnesspkfire.o(.bss .bss.* COMMON)
		*libssb_game.a:itlinkbomb.o(.bss .bss.* COMMON)
		__ps2_ovl3_bss_end = .;
		. = ALIGN(16); __ps2_ovl4_bss_start = .;
		*libssb_game.a:scvsbattle.o(.bss .bss.* COMMON)
		*libssb_game.a:scvsbattlefiles.o(.bss .bss.* COMMON)
		__ps2_ovl4_bss_end = .;
		. = ALIGN(16); __ps2_ovl5_bss_start = .;
		*libssb_game.a:mvunknownmario.o(.bss .bss.* COMMON)
		__ps2_ovl5_bss_end = .;
		. = ALIGN(16); __ps2_ovl6_bss_start = .;
		*libssb_game.a:sc1pbonusstage.o(.bss .bss.* COMMON)
		*libssb_game.a:sc1pbonusstagefiles.o(.bss .bss.* COMMON)
		*libssb_game.a:ittarget.o(.bss .bss.* COMMON)
		__ps2_ovl6_bss_end = .;
		. = ALIGN(16); __ps2_ovl7_bss_start = .;
		*libssb_game.a:sc1ptrainingmode.o(.bss .bss.* COMMON)
		__ps2_ovl7_bss_end = .;
		. = ALIGN(16); __ps2_ovl8_bss_start = .;
		*libssb_game.a:ovl8_0.o(.bss .bss.* COMMON)
		*libssb_game.a:ovl8_1.o(.bss .bss.* COMMON)
		*libssb_game.a:ovl8_2.o(.bss .bss.* COMMON)
		*libssb_game.a:ovl8_3.o(.bss .bss.* COMMON)
		*libssb_game.a:ovl8_4.o(.bss .bss.* COMMON)
		*libssb_game.a:ovl8_5.o(.bss .bss.* COMMON)
		*libssb_game.a:ovl8_6.o(.bss .bss.* COMMON)
		*libssb_game.a:ovl8_6_1.o(.bss .bss.* COMMON)
		*libssb_game.a:ovl8_7.o(.bss .bss.* COMMON)
		*libssb_game.a:ovl8_8.o(.bss .bss.* COMMON)
		*libssb_game.a:ovl8_8_2.o(.bss .bss.* COMMON)
		*libssb_game.a:ovl8_9.o(.bss .bss.* COMMON)
		*libssb_game.a:ovl8_10.o(.bss .bss.* COMMON)
		*libssb_game.a:ovl8_11.o(.bss .bss.* COMMON)
		*libssb_game.a:ovl8_11_1.o(.bss .bss.* COMMON)
		*libssb_game.a:ovl8_12.o(.bss .bss.* COMMON)
		*libssb_game.a:ovl8_13.o(.bss .bss.* COMMON)
		*libssb_game.a:ovl8_13_2.o(.bss .bss.* COMMON)
		*libssb_game.a:ovl8_14.o(.bss .bss.* COMMON)
		*libssb_game.a:ovl8_15.o(.bss .bss.* COMMON)
		*libssb_game.a:ovl8_16.o(.bss .bss.* COMMON)
		*libssb_game.a:ovl8_17.o(.bss .bss.* COMMON)
		*libssb_game.a:ovl8_18.o(.bss .bss.* COMMON)
		*libssb_game.a:ovl8_19.o(.bss .bss.* COMMON)
		*libssb_game.a:ovl8_20.o(.bss .bss.* COMMON)
		*libssb_game.a:ovl8_21.o(.bss .bss.* COMMON)
		*libssb_game.a:ovl8_22.o(.bss .bss.* COMMON)
		*libssb_game.a:ovl8_23.o(.bss .bss.* COMMON)
		*libssb_game.a:ovl8_24.o(.bss .bss.* COMMON)
		*libssb_game.a:ovl8_25.o(.bss .bss.* COMMON)
		*libssb_game.a:ovl8_26.o(.bss .bss.* COMMON)
		*libssb_game.a:ovl8_27.o(.bss .bss.* COMMON)
		*libssb_game.a:ovl8_28.o(.bss .bss.* COMMON)
		*libssb_game.a:ovl8_29.o(.bss .bss.* COMMON)
		*libssb_game.a:ovl8_30.o(.bss .bss.* COMMON)
		*libssb_game.a:ovl8_31.o(.bss .bss.* COMMON)
		*libssb_game.a:ovl8_32.o(.bss .bss.* COMMON)
		*libssb_game.a:ovl8_bss.o(.bss .bss.* COMMON)
		__ps2_ovl8_bss_end = .;
		. = ALIGN(16); __ps2_ovl9_bss_start = .;
		*libssb_game.a:dbmenu.o(.bss .bss.* COMMON)
		__ps2_ovl9_bss_end = .;
		. = ALIGN(16); __ps2_ovl10_bss_start = .;
		*libssb_game.a:mntitle.o(.bss .bss.* COMMON)
		*libssb_game.a:mntitlefiles.o(.bss .bss.* COMMON)
		__ps2_ovl10_bss_end = .;
		. = ALIGN(16); __ps2_ovl11_bss_start = .;
		*libssb_game.a:mnnocontroller.o(.bss .bss.* COMMON)
		*libssb_game.a:mnnocontrollerfiles.o(.bss .bss.* COMMON)
		__ps2_ovl11_bss_end = .;
		. = ALIGN(16); __ps2_ovl12_bss_start = .;
		*libssb_game.a:dbmaps.o(.bss .bss.* COMMON)
		__ps2_ovl12_bss_end = .;
		. = ALIGN(16); __ps2_ovl13_bss_start = .;
		*libssb_game.a:dbcube.o(.bss .bss.* COMMON)
		__ps2_ovl13_bss_end = .;
		. = ALIGN(16); __ps2_ovl14_bss_start = .;
		*libssb_game.a:dbbattle.o(.bss .bss.* COMMON)
		__ps2_ovl14_bss_end = .;
		. = ALIGN(16); __ps2_ovl15_bss_start = .;
		*libssb_game.a:dbfalls.o(.bss .bss.* COMMON)
		__ps2_ovl15_bss_end = .;
		. = ALIGN(16); __ps2_ovl16_bss_start = .;
		*libssb_game.a:mnunusedfighters.o(.bss .bss.* COMMON)
		__ps2_ovl16_bss_end = .;
		. = ALIGN(16); __ps2_ovl17_bss_start = .;
		*libssb_game.a:mnmodeselect.o(.bss .bss.* COMMON)
		__ps2_ovl17_bss_end = .;
		. = ALIGN(16); __ps2_ovl18_bss_start = .;
		*libssb_game.a:mn1pmode.o(.bss .bss.* COMMON)
		__ps2_ovl18_bss_end = .;
		. = ALIGN(16); __ps2_ovl19_bss_start = .;
		*libssb_game.a:mnvsmode.o(.bss .bss.* COMMON)
		__ps2_ovl19_bss_end = .;
		. = ALIGN(16); __ps2_ovl20_bss_start = .;
		*libssb_game.a:mnvsoptions.o(.bss .bss.* COMMON)
		__ps2_ovl20_bss_end = .;
		. = ALIGN(16); __ps2_ovl21_bss_start = .;
		*libssb_game.a:mnvsitemswitch.o(.bss .bss.* COMMON)
		__ps2_ovl21_bss_end = .;
		. = ALIGN(16); __ps2_ovl22_bss_start = .;
		*libssb_game.a:mnmessage.o(.bss .bss.* COMMON)
		__ps2_ovl22_bss_end = .;
		. = ALIGN(16); __ps2_ovl23_bss_start = .;
		*libssb_game.a:sc1pchallenger.o(.bss .bss.* COMMON)
		__ps2_ovl23_bss_end = .;
		. = ALIGN(16); __ps2_ovl24_bss_start = .;
		*libssb_game.a:sc1pintro.o(.bss .bss.* COMMON)
		__ps2_ovl24_bss_end = .;
		. = ALIGN(16); __ps2_ovl25_bss_start = .;
		*libssb_game.a:mnscreenadjust.o(.bss .bss.* COMMON)
		__ps2_ovl25_bss_end = .;
		. = ALIGN(16); __ps2_ovl26_bss_start = .;
		*libssb_game.a:mnplayersvs.o(.bss .bss.* COMMON)
		__ps2_ovl26_bss_end = .;
		. = ALIGN(16); __ps2_ovl27_bss_start = .;
		*libssb_game.a:mnplayers1pgame.o(.bss .bss.* COMMON)
		__ps2_ovl27_bss_end = .;
		. = ALIGN(16); __ps2_ovl28_bss_start = .;
		*libssb_game.a:mnplayers1ptraining.o(.bss .bss.* COMMON)
		__ps2_ovl28_bss_end = .;
		. = ALIGN(16); __ps2_ovl29_bss_start = .;
		*libssb_game.a:mnplayers1pbonus.o(.bss .bss.* COMMON)
		__ps2_ovl29_bss_end = .;
		. = ALIGN(16); __ps2_ovl30_bss_start = .;
		*libssb_game.a:mnmaps.o(.bss .bss.* COMMON)
		__ps2_ovl30_bss_end = .;
		. = ALIGN(16); __ps2_ovl31_bss_start = .;
		*libssb_game.a:mnvsresults.o(.bss .bss.* COMMON)
		__ps2_ovl31_bss_end = .;
		. = ALIGN(16); __ps2_ovl32_bss_start = .;
		*libssb_game.a:mnvsrecord.o(.bss .bss.* COMMON)
		__ps2_ovl32_bss_end = .;
		. = ALIGN(16); __ps2_ovl33_bss_start = .;
		*libssb_game.a:mncharacters.o(.bss .bss.* COMMON)
		__ps2_ovl33_bss_end = .;
		. = ALIGN(16); __ps2_ovl34_bss_start = .;
		*libssb_game.a:mvopeningroom.o(.bss .bss.* COMMON)
		__ps2_ovl34_bss_end = .;
		. = ALIGN(16); __ps2_ovl35_bss_start = .;
		*libssb_game.a:mvopeningportraits.o(.bss .bss.* COMMON)
		__ps2_ovl35_bss_end = .;
		. = ALIGN(16); __ps2_ovl36_bss_start = .;
		*libssb_game.a:mvopeningmario.o(.bss .bss.* COMMON)
		__ps2_ovl36_bss_end = .;
		. = ALIGN(16); __ps2_ovl37_bss_start = .;
		*libssb_game.a:mvopeningdonkey.o(.bss .bss.* COMMON)
		__ps2_ovl37_bss_end = .;
		. = ALIGN(16); __ps2_ovl38_bss_start = .;
		*libssb_game.a:mvopeningsamus.o(.bss .bss.* COMMON)
		__ps2_ovl38_bss_end = .;
		. = ALIGN(16); __ps2_ovl39_bss_start = .;
		*libssb_game.a:mvopeningfox.o(.bss .bss.* COMMON)
		__ps2_ovl39_bss_end = .;
		. = ALIGN(16); __ps2_ovl40_bss_start = .;
		*libssb_game.a:mvopeninglink.o(.bss .bss.* COMMON)
		__ps2_ovl40_bss_end = .;
		. = ALIGN(16); __ps2_ovl41_bss_start = .;
		*libssb_game.a:mvopeningyoshi.o(.bss .bss.* COMMON)
		__ps2_ovl41_bss_end = .;
		. = ALIGN(16); __ps2_ovl42_bss_start = .;
		*libssb_game.a:mvopeningpikachu.o(.bss .bss.* COMMON)
		__ps2_ovl42_bss_end = .;
		. = ALIGN(16); __ps2_ovl43_bss_start = .;
		*libssb_game.a:mvopeningkirby.o(.bss .bss.* COMMON)
		__ps2_ovl43_bss_end = .;
		. = ALIGN(16); __ps2_ovl44_bss_start = .;
		*libssb_game.a:mvopeningrun.o(.bss .bss.* COMMON)
		__ps2_ovl44_bss_end = .;
		. = ALIGN(16); __ps2_ovl45_bss_start = .;
		*libssb_game.a:mvopeningyoster.o(.bss .bss.* COMMON)
		__ps2_ovl45_bss_end = .;
		. = ALIGN(16); __ps2_ovl46_bss_start = .;
		*libssb_game.a:mvopeningcliff.o(.bss .bss.* COMMON)
		__ps2_ovl46_bss_end = .;
		. = ALIGN(16); __ps2_ovl47_bss_start = .;
		*libssb_game.a:mvopeningstandoff.o(.bss .bss.* COMMON)
		__ps2_ovl47_bss_end = .;
		. = ALIGN(16); __ps2_ovl48_bss_start = .;
		*libssb_game.a:mvopeningyamabuki.o(.bss .bss.* COMMON)
		__ps2_ovl48_bss_end = .;
		. = ALIGN(16); __ps2_ovl49_bss_start = .;
		*libssb_game.a:mvopeningclash.o(.bss .bss.* COMMON)
		__ps2_ovl49_bss_end = .;
		. = ALIGN(16); __ps2_ovl50_bss_start = .;
		*libssb_game.a:mvopeningsector.o(.bss .bss.* COMMON)
		__ps2_ovl50_bss_end = .;
		. = ALIGN(16); __ps2_ovl51_bss_start = .;
		*libssb_game.a:mvopeningjungle.o(.bss .bss.* COMMON)
		__ps2_ovl51_bss_end = .;
		. = ALIGN(16); __ps2_ovl52_bss_start = .;
		*libssb_game.a:mvopeningnewcomers.o(.bss .bss.* COMMON)
		__ps2_ovl52_bss_end = .;
		. = ALIGN(16); __ps2_ovl53_bss_start = .;
		*libssb_game.a:mnbackupclear.o(.bss .bss.* COMMON)
		__ps2_ovl53_bss_end = .;
		. = ALIGN(16); __ps2_ovl54_bss_start = .;
		*libssb_game.a:mvending.o(.bss .bss.* COMMON)
		__ps2_ovl54_bss_end = .;
		. = ALIGN(16); __ps2_ovl55_bss_start = .;
		*libssb_game.a:mn1pcontinue.o(.bss .bss.* COMMON)
		__ps2_ovl55_bss_end = .;
		. = ALIGN(16); __ps2_ovl56_bss_start = .;
		*libssb_game.a:sc1pstageclear.o(.bss .bss.* COMMON)
		__ps2_ovl56_bss_end = .;
		. = ALIGN(16); __ps2_ovl57_bss_start = .;
		*libssb_game.a:mncongra.o(.bss .bss.* COMMON)
		__ps2_ovl57_bss_end = .;
		. = ALIGN(16); __ps2_ovl58_bss_start = .;
		*libssb_game.a:mnstartup.o(.bss .bss.* COMMON)
		__ps2_ovl58_bss_end = .;
		. = ALIGN(16); __ps2_ovl59_bss_start = .;
		*libssb_game.a:scstaffroll.o(.bss .bss.* COMMON)
		__ps2_ovl59_bss_end = .;
		. = ALIGN(16); __ps2_ovl60_bss_start = .;
		*libssb_game.a:mnoption.o(.bss .bss.* COMMON)
		__ps2_ovl60_bss_end = .;
		. = ALIGN(16); __ps2_ovl61_bss_start = .;
		*libssb_game.a:mndata.o(.bss .bss.* COMMON)
		__ps2_ovl61_bss_end = .;
		. = ALIGN(16); __ps2_ovl62_bss_start = .;
		*libssb_game.a:mnsoundtest.o(.bss .bss.* COMMON)
		__ps2_ovl62_bss_end = .;
		. = ALIGN(16); __ps2_ovl63_bss_start = .;
		*libssb_game.a:scexplain.o(.bss .bss.* COMMON)
		*libssb_game.a:scexplainfiles.o(.bss .bss.* COMMON)
		__ps2_ovl63_bss_end = .;
		. = ALIGN(16); __ps2_ovl64_bss_start = .;
		*libssb_game.a:scautodemo.o(.bss .bss.* COMMON)
		*libssb_game.a:scautodemofiles.o(.bss .bss.* COMMON)
		__ps2_ovl64_bss_end = .;
		. = ALIGN(16); __ps2_ovl65_bss_start = .;
		*libssb_game.a:sc1pgame.o(.bss .bss.* COMMON)
		*libssb_game.a:sc1pgameboss.o(.bss .bss.* COMMON)
		__ps2_ovl65_bss_end = .;
		. = ALIGN(16); __ps2_scmanager_bss_start = .;
		*libssb_game.a:scmanager.o(.bss .bss.* COMMON)
		__ps2_scmanager_bss_end = .;
		*(.bss)
		*(.bss.*)
		*(.gnu.linkonce.b*)
		*(COMMON)
	}
	_end_bss = .;

	/*
	 * Optional hardware services that were not part of the proven early
	 * runtime image live after BSS. In particular, referencing embedded
	 * sdr.irx used to insert ~6 KiB into .data and move every static/game
	 * address even though audio had not executed yet.
	 */
	.late_text ALIGN(16) : {
		*(.late_text)
		*(.late_text.*)
	}
	.late_rodata ALIGN(16) : {
		*(.late_rodata)
		*(.late_rodata.*)
	}
	.late_irx ALIGN(128) : {
		*sdr_irx.o(.data .data.*)
	}

	_end = . ;
	PROVIDE(end = .);

	.spad 0x70000000: {
		*(.spad)
	}

	PROVIDE(_heap_size = -1);
	PROVIDE(_stack = -1);
	PROVIDE(_stack_size = 128 * 1024);
}
